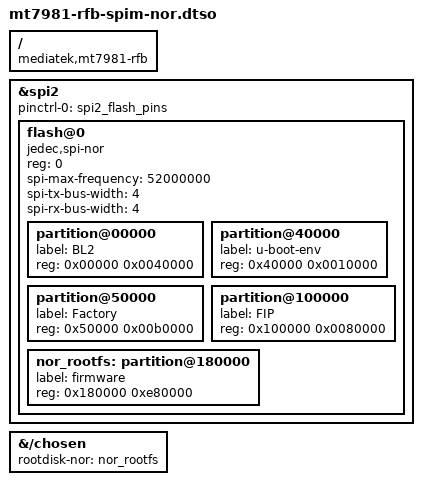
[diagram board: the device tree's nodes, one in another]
// SPDX-License-Identifier: (GPL-2.0 OR MIT)
/*
 * Copyright (C) 2022 MediaTek Inc.
 * Author: Sam.Shih <sam.shih@mediatek.com>
 */

/dts-v1/;
/plugin/;

/ {
	compatible = "mediatek,mt7981-rfb", "mediatek,mt7981";

	fragment@0 {
		target = <&spi2>;
		__overlay__ {
			pinctrl-names = "default";
			pinctrl-0 = <&spi2_flash_pins>;
			status = "okay";

			flash@0 {
				#address-cells = <1>;
				#size-cells = <1>;
				compatible = "jedec,spi-nor";
				reg = <0>;
				spi-max-frequency = <52000000>;
				spi-tx-bus-width = <4>;
				spi-rx-bus-width = <4>;

				partition@00000 {
					label = "BL2";
					reg = <0x00000 0x0040000>;
				};
				partition@40000 {
					label = "u-boot-env";
					reg = <0x40000 0x0010000>;
				};
				partition@50000 {
					label = "Factory";
					reg = <0x50000 0x00b0000>;
				};
				partition@100000 {
					label = "FIP";
					reg = <0x100000 0x0080000>;
				};
				nor_rootfs: partition@180000 {
					label = "firmware";
					reg = <0x180000 0xe80000>;
				};
			};
		};
	};

	fragment@1 {
		target-path = "/chosen";
		__overlay__ {
			rootdisk-nor = <&nor_rootfs>;
		};
	};
};
